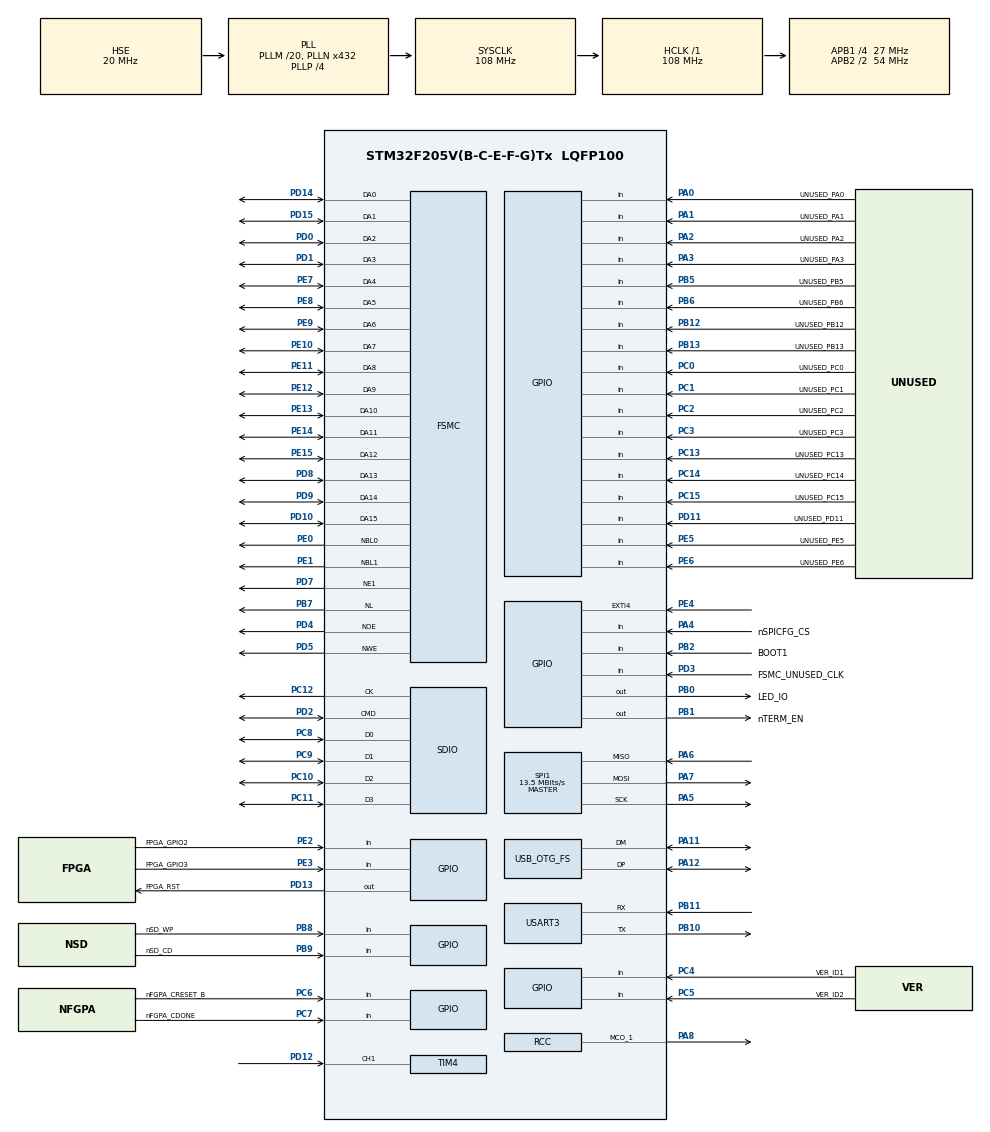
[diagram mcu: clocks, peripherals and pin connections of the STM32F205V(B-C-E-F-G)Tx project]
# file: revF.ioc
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Dma.MEMTOMEM.0.Direction=DMA_MEMORY_TO_MEMORY
Dma.MEMTOMEM.0.FIFOMode=DMA_FIFOMODE_ENABLE
Dma.MEMTOMEM.0.FIFOThreshold=DMA_FIFO_THRESHOLD_FULL
Dma.MEMTOMEM.0.Instance=DMA2_Stream0
Dma.MEMTOMEM.0.MemBurst=DMA_MBURST_INC8
Dma.MEMTOMEM.0.MemDataAlignment=DMA_MDATAALIGN_HALFWORD
Dma.MEMTOMEM.0.MemInc=DMA_MINC_DISABLE
Dma.MEMTOMEM.0.Mode=DMA_NORMAL
Dma.MEMTOMEM.0.PeriphBurst=DMA_PBURST_INC4
Dma.MEMTOMEM.0.PeriphDataAlignment=DMA_PDATAALIGN_WORD
Dma.MEMTOMEM.0.PeriphInc=DMA_PINC_ENABLE
Dma.MEMTOMEM.0.Priority=DMA_PRIORITY_LOW
Dma.MEMTOMEM.1.Direction=DMA_MEMORY_TO_MEMORY
Dma.MEMTOMEM.1.FIFOMode=DMA_FIFOMODE_ENABLE
Dma.MEMTOMEM.1.FIFOThreshold=DMA_FIFO_THRESHOLD_FULL
Dma.MEMTOMEM.1.Instance=DMA2_Stream1
Dma.MEMTOMEM.1.MemBurst=DMA_MBURST_INC4
Dma.MEMTOMEM.1.MemDataAlignment=DMA_MDATAALIGN_WORD
Dma.MEMTOMEM.1.MemInc=DMA_MINC_ENABLE
Dma.MEMTOMEM.1.Mode=DMA_NORMAL
Dma.MEMTOMEM.1.PeriphBurst=DMA_PBURST_INC8
Dma.MEMTOMEM.1.PeriphDataAlignment=DMA_PDATAALIGN_HALFWORD
Dma.MEMTOMEM.1.PeriphInc=DMA_PINC_DISABLE
Dma.MEMTOMEM.1.Priority=DMA_PRIORITY_LOW
Dma.Request0=MEMTOMEM
Dma.Request1=MEMTOMEM
Dma.Request2=SDIO_TX
Dma.Request3=SDIO_RX
Dma.SDIO_RX.3.Direction=DMA_PERIPH_TO_MEMORY
Dma.SDIO_RX.3.FIFOMode=DMA_FIFOMODE_ENABLE
Dma.SDIO_RX.3.FIFOThreshold=DMA_FIFO_THRESHOLD_FULL
Dma.SDIO_RX.3.Instance=DMA2_Stream6
Dma.SDIO_RX.3.MemBurst=DMA_MBURST_INC4
Dma.SDIO_RX.3.MemDataAlignment=DMA_MDATAALIGN_WORD
Dma.SDIO_RX.3.MemInc=DMA_MINC_ENABLE
Dma.SDIO_RX.3.Mode=DMA_PFCTRL
Dma.SDIO_RX.3.PeriphBurst=DMA_PBURST_INC4
Dma.SDIO_RX.3.PeriphDataAlignment=DMA_PDATAALIGN_WORD
Dma.SDIO_RX.3.PeriphInc=DMA_PINC_DISABLE
Dma.SDIO_RX.3.Priority=DMA_PRIORITY_VERY_HIGH
Dma.SDIO_TX.2.Direction=DMA_MEMORY_TO_PERIPH
Dma.SDIO_TX.2.FIFOMode=DMA_FIFOMODE_ENABLE
Dma.SDIO_TX.2.FIFOThreshold=DMA_FIFO_THRESHOLD_FULL
Dma.SDIO_TX.2.Instance=DMA2_Stream3
Dma.SDIO_TX.2.MemBurst=DMA_MBURST_INC4
Dma.SDIO_TX.2.MemDataAlignment=DMA_MDATAALIGN_WORD
Dma.SDIO_TX.2.MemInc=DMA_MINC_ENABLE
Dma.SDIO_TX.2.Mode=DMA_PFCTRL
Dma.SDIO_TX.2.PeriphBurst=DMA_PBURST_INC4
Dma.SDIO_TX.2.PeriphDataAlignment=DMA_PDATAALIGN_WORD
Dma.SDIO_TX.2.PeriphInc=DMA_PINC_DISABLE
Dma.SDIO_TX.2.Priority=DMA_PRIORITY_VERY_HIGH
FSMC.AddressHoldTime1=1
FSMC.AddressSetupTime1=2
FSMC.BusTurnAroundDuration1=1
FSMC.DataSetupTime1=4
FSMC.WriteOperation1=FSMC_WRITE_OPERATION_ENABLE
Mcu.Family=STM32F2
Mcu.Name=STM32F205V(B-C-E-F-G)Tx
Mcu.Package=LQFP100
NVIC.DMA2_Stream3_IRQn=true\:2\:0\:true\:false\:true\:true\:true
NVIC.DMA2_Stream6_IRQn=true\:2\:0\:true\:false\:true\:true\:true
NVIC.EXTI4_IRQn=true\:10\:0\:true\:false\:true\:true\:true
NVIC.OTG_FS_IRQn=true\:1\:0\:true\:false\:true\:true\:true
NVIC.PriorityGroup=NVIC_PRIORITYGROUP_4
NVIC.SDIO_IRQn=true\:8\:0\:true\:false\:true\:true\:true
PA0-WKUP.GPIO_Label=UNUSED_PA0
PA0-WKUP.GPIO_PuPd=GPIO_PULLDOWN
PA0-WKUP.Signal=GPIO_Input
PA1.GPIO_Label=UNUSED_PA1
PA1.GPIO_PuPd=GPIO_PULLDOWN
PA1.Signal=GPIO_Input
PA11.Mode=Device_Only
PA11.Signal=USB_OTG_FS_DM
PA12.Mode=Device_Only
PA12.Signal=USB_OTG_FS_DP
PA2.GPIO_Label=UNUSED_PA2
PA2.GPIO_PuPd=GPIO_PULLDOWN
PA2.Signal=GPIO_Input
PA3.GPIO_Label=UNUSED_PA3
PA3.GPIO_PuPd=GPIO_PULLDOWN
PA3.Signal=GPIO_Input
PA4.GPIO_Label=nSPICFG_CS
PA4.GPIO_Mode=GPIO_MODE_INPUT
PA4.GPIO_PuPd=GPIO_NOPULL
PA4.Signal=GPIO_Input
PA5.Mode=Full_Duplex_Master
PA5.Signal=SPI1_SCK
PA6.Mode=Full_Duplex_Master
PA6.Signal=SPI1_MISO
PA7.Mode=Full_Duplex_Master
PA7.Signal=SPI1_MOSI
PA8.GPIO_Speed=GPIO_SPEED_FREQ_VERY_HIGH
PA8.Mode=Clock-out-1
PA8.Signal=RCC_MCO_1
PB0.GPIO_Label=LED_IO
PB0.GPIO_ModeDefaultOutputPP=GPIO_MODE_OUTPUT_PP
PB0.GPIO_PuPd=GPIO_PULLDOWN
PB0.Signal=GPIO_Output
PB1.GPIO_Label=nTERM_EN
PB1.GPIO_PuPd=GPIO_NOPULL
PB1.Signal=GPIO_Output
PB10.Mode=Asynchronous
PB10.Signal=USART3_TX
PB11.Mode=Asynchronous
PB11.Signal=USART3_RX
PB12.GPIO_Label=UNUSED_PB12
PB12.GPIO_PuPd=GPIO_PULLDOWN
PB12.Signal=GPIO_Input
PB13.GPIO_Label=UNUSED_PB13
PB13.GPIO_PuPd=GPIO_PULLDOWN
PB13.Signal=GPIO_Input
PB2.GPIO_Label=BOOT1
PB2.Signal=GPIO_Input
PB5.GPIO_Label=UNUSED_PB5
PB5.Signal=GPIO_Input
PB6.GPIO_Label=UNUSED_PB6
PB6.Signal=GPIO_Input
PB7.GPIO_Speed_High_Default=GPIO_SPEED_FREQ_MEDIUM
PB7.Signal=FSMC_NL
PB8.GPIO_Label=nSD_WP
PB8.GPIO_PuPd=GPIO_PULLUP
PB8.Signal=GPIO_Input
PB9.GPIO_Label=nSD_CD
PB9.GPIO_PuPd=GPIO_PULLUP
PB9.Signal=GPIO_Input
PC0.GPIO_Label=UNUSED_PC0
PC0.GPIO_PuPd=GPIO_PULLDOWN
PC0.Signal=GPIO_Input
PC1.GPIO_Label=UNUSED_PC1
PC1.GPIO_PuPd=GPIO_PULLDOWN
PC1.Signal=GPIO_Input
PC10.GPIO_PuPd=GPIO_PULLUP
PC10.Mode=SD_4_bits_Wide_bus
PC10.Signal=SDIO_D2
PC11.GPIO_PuPd=GPIO_PULLUP
PC11.Mode=SD_4_bits_Wide_bus
PC11.Signal=SDIO_D3
PC12.Mode=SD_4_bits_Wide_bus
PC12.Signal=SDIO_CK
PC13.GPIO_Label=UNUSED_PC13
PC13.GPIO_PuPd=GPIO_PULLDOWN
PC13.Signal=GPIO_Input
PC14-OSC32_IN.GPIO_Label=UNUSED_PC14
PC14-OSC32_IN.GPIO_PuPd=GPIO_PULLDOWN
PC14-OSC32_IN.Signal=GPIO_Input
PC15-OSC32_OUT.GPIO_Label=UNUSED_PC15
PC15-OSC32_OUT.GPIO_PuPd=GPIO_PULLDOWN
PC15-OSC32_OUT.Signal=GPIO_Input
PC2.GPIO_Label=UNUSED_PC2
PC2.GPIO_PuPd=GPIO_PULLDOWN
PC2.Signal=GPIO_Input
PC3.GPIO_Label=UNUSED_PC3
PC3.GPIO_PuPd=GPIO_PULLDOWN
PC3.Signal=GPIO_Input
PC4.GPIO_Label=VER_ID1
PC4.GPIO_PuPd=GPIO_PULLUP
PC4.Signal=GPIO_Input
PC5.GPIO_Label=VER_ID2
PC5.GPIO_PuPd=GPIO_PULLUP
PC5.Signal=GPIO_Input
PC6.GPIO_Label=nFGPA_CRESET_B
PC6.GPIO_PuPd=GPIO_NOPULL
PC6.Signal=GPIO_Input
PC7.GPIO_Label=nFGPA_CDONE
PC7.GPIO_PuPd=GPIO_NOPULL
PC7.Signal=GPIO_Input
PC8.GPIO_PuPd=GPIO_PULLUP
PC8.Mode=SD_4_bits_Wide_bus
PC8.Signal=SDIO_D0
PC9.GPIO_PuPd=GPIO_PULLUP
PC9.Mode=SD_4_bits_Wide_bus
PC9.Signal=SDIO_D1
PD0.GPIO_Speed_High_Default=GPIO_SPEED_FREQ_MEDIUM
PD0.Mode=16b-da1
PD0.Signal=FSMC_DA2
PD1.GPIO_Speed_High_Default=GPIO_SPEED_FREQ_MEDIUM
PD1.Mode=16b-da1
PD1.Signal=FSMC_DA3
PD10.GPIO_Speed_High_Default=GPIO_SPEED_FREQ_MEDIUM
PD10.Mode=16b-da1
PD10.Signal=FSMC_DA15
PD11.GPIO_Label=UNUSED_PD11
PD11.GPIO_PuPd=GPIO_PULLDOWN
PD11.Signal=GPIO_Input
PD12.Signal=S_TIM4_CH1
PD13.GPIO_Label=FPGA_RST
PD13.GPIO_PuPd=GPIO_NOPULL
PD13.Signal=GPIO_Output
PD14.GPIO_Speed_High_Default=GPIO_SPEED_FREQ_MEDIUM
PD14.Mode=16b-da1
PD14.Signal=FSMC_DA0
PD15.GPIO_Speed_High_Default=GPIO_SPEED_FREQ_MEDIUM
PD15.Mode=16b-da1
PD15.Signal=FSMC_DA1
PD2.GPIO_PuPd=GPIO_PULLUP
PD2.Mode=SD_4_bits_Wide_bus
PD2.Signal=SDIO_CMD
PD3.GPIO_Label=FSMC_UNUSED_CLK
PD3.GPIO_PuPd=GPIO_PULLDOWN
PD3.Signal=GPIO_Input
PD4.GPIO_Speed_High_Default=GPIO_SPEED_FREQ_MEDIUM
PD4.Mode=MuxedPsram1
PD4.Signal=FSMC_NOE
PD5.GPIO_Speed_High_Default=GPIO_SPEED_FREQ_MEDIUM
PD5.Mode=MuxedPsram1
PD5.Signal=FSMC_NWE
PD7.GPIO_Speed_High_Default=GPIO_SPEED_FREQ_MEDIUM
PD7.Mode=NorPsramChipSelect1_1
PD7.Signal=FSMC_NE1
PD8.GPIO_Speed_High_Default=GPIO_SPEED_FREQ_MEDIUM
PD8.Mode=16b-da1
PD8.Signal=FSMC_DA13
PD9.GPIO_Speed_High_Default=GPIO_SPEED_FREQ_MEDIUM
PD9.Mode=16b-da1
PD9.Signal=FSMC_DA14
PE0.GPIO_Speed_High_Default=GPIO_SPEED_FREQ_MEDIUM
PE0.Mode=2ByteEnable1
PE0.Signal=FSMC_NBL0
PE1.GPIO_Speed_High_Default=GPIO_SPEED_FREQ_MEDIUM
PE1.Mode=2ByteEnable1
PE1.Signal=FSMC_NBL1
PE10.GPIO_Speed_High_Default=GPIO_SPEED_FREQ_MEDIUM
PE10.Mode=16b-da1
PE10.Signal=FSMC_DA7
PE11.GPIO_Speed_High_Default=GPIO_SPEED_FREQ_MEDIUM
PE11.Mode=16b-da1
PE11.Signal=FSMC_DA8
PE12.GPIO_Speed_High_Default=GPIO_SPEED_FREQ_MEDIUM
PE12.Mode=16b-da1
PE12.Signal=FSMC_DA9
PE13.GPIO_Speed_High_Default=GPIO_SPEED_FREQ_MEDIUM
PE13.Mode=16b-da1
PE13.Signal=FSMC_DA10
PE14.GPIO_Speed_High_Default=GPIO_SPEED_FREQ_MEDIUM
PE14.Mode=16b-da1
PE14.Signal=FSMC_DA11
PE15.GPIO_Speed_High_Default=GPIO_SPEED_FREQ_MEDIUM
PE15.Mode=16b-da1
PE15.Signal=FSMC_DA12
PE2.GPIO_Label=FPGA_GPIO2
PE2.GPIO_PuPd=GPIO_PULLDOWN
PE2.Signal=GPIO_Input
PE3.GPIO_Label=FPGA_GPIO3
PE3.GPIO_PuPd=GPIO_PULLDOWN
PE3.Signal=GPIO_Input
PE4.Signal=GPXTI4
PE5.GPIO_Label=UNUSED_PE5
PE5.GPIO_PuPd=GPIO_PULLDOWN
PE5.Signal=GPIO_Input
PE6.GPIO_Label=UNUSED_PE6
PE6.GPIO_PuPd=GPIO_PULLDOWN
PE6.Signal=GPIO_Input
PE7.GPIO_Speed_High_Default=GPIO_SPEED_FREQ_MEDIUM
PE7.Mode=16b-da1
PE7.Signal=FSMC_DA4
PE8.GPIO_Speed_High_Default=GPIO_SPEED_FREQ_MEDIUM
PE8.Mode=16b-da1
PE8.Signal=FSMC_DA5
PE9.GPIO_Speed_High_Default=GPIO_SPEED_FREQ_MEDIUM
PE9.Mode=16b-da1
PE9.Signal=FSMC_DA6
PH0-OSC_IN.Mode=HSE-External-Oscillator
PH0-OSC_IN.Signal=RCC_OSC_IN
PH1-OSC_OUT.Mode=HSE-External-Oscillator
PH1-OSC_OUT.Signal=RCC_OSC_OUT
ProjectManager.HeapSize=0x200
ProjectManager.StackSize=0x400
ProjectManager.TargetToolchain=TrueSTUDIO
RCC.48MHZClocksFreq_Value=48000000
RCC.AHBFreq_Value=108000000
RCC.APB1CLKDivider=RCC_HCLK_DIV4
RCC.APB1Freq_Value=27000000
RCC.APB1TimFreq_Value=54000000
RCC.APB2CLKDivider=RCC_HCLK_DIV2
RCC.APB2Freq_Value=54000000
RCC.APB2TimFreq_Value=108000000
RCC.CortexFreq_Value=108000000
RCC.HCLKFreq_Value=108000000
RCC.HSE_VALUE=20000000
RCC.HSI_VALUE=16000000
RCC.LSE_VALUE=32768
RCC.PLLM=20
RCC.PLLN=432
RCC.PLLP=RCC_PLLP_DIV4
RCC.PLLQ=9
RCC.PLLSourceVirtual=RCC_PLLSOURCE_HSE
RCC.RCC_MCO1Source=RCC_MCO1SOURCE_PLLCLK
RCC.SYSCLKFreq_VALUE=108000000
RCC.SYSCLKSource=RCC_SYSCLKSOURCE_PLLCLK
RCC.VCOOutputFreq_Value=432000000
SDIO.WideMode=SDIO_BUS_WIDE_4B
SH.FSMC_NL.0=FSMC_NL,AddressValid1
SH.S_TIM4_CH1.0=TIM4_CH1,TriggerSource_TI1FP1
SPI1.BaudRatePrescaler=SPI_BAUDRATEPRESCALER_4
SPI1.CLKPhase=SPI_PHASE_2EDGE
SPI1.CLKPolarity=SPI_POLARITY_HIGH
SPI1.CalculateBaudRate=13.5 MBits/s
SPI1.Direction=SPI_DIRECTION_2LINES
SPI1.Mode=SPI_MODE_MASTER
SPI1.VirtualType=VM_MASTER
USART3.VirtualMode=VM_ASYNC
USB_DEVICE.CLASS_NAME_FS=MSC
USB_DEVICE.VirtualMode-MSC_FS=Msc
USB_DEVICE.VirtualModeFS=Msc_FS
USB_OTG_FS.VirtualMode=Device_Only
VP_TIM4_VS_ControllerModeClock.Mode=Clock Mode
VP_USB_DEVICE_VS_USB_DEVICE_MSC_FS.Mode=MSC_FS
board=SCSI2SD-V6

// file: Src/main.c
/* USER CODE BEGIN Header */
/**
  ******************************************************************************
  * @file           : main.c
  * @brief          : Main program body
  ******************************************************************************
  * @attention
  *
  * <h2><center>&copy; Copyright (c) 2021 STMicroelectronics.
  * All rights reserved.</center></h2>
  *
  * This software component is licensed by ST under Ultimate Liberty license
  * SLA0044, the "License"; You may not use this file except in compliance with
  * the License. You may obtain a copy of the License at:
  *                             www.st.com/SLA0044
  *
  ******************************************************************************
  */
/* USER CODE END Header */

#include "main.h"
#include "dma.h"
#include "sdio.h"
#include "spi.h"
#include "tim.h"
#include "usart.h"
#include "usb_device.h"
#include "gpio.h"
#include "fsmc.h"

/* USER CODE BEGIN PV */
/* Private variables ---------------------------------------------------------*/

/* USER CODE END PV */

void SystemClock_Config(void);
/* USER CODE BEGIN PFP */
/* Private function prototypes -----------------------------------------------*/
void mainEarlyInit();
void mainInit();
void mainLoop();

/* USER CODE END PFP */

int main(void)
{
  /* USER CODE BEGIN 1 */
  mainEarlyInit();

  /* USER CODE END 1 */

  /* MCU Configuration--------------------------------------------------------*/

  /* Reset of all peripherals, Initializes the Flash interface and the Systick. */
  HAL_Init();

  /* Configure the system clock */
  SystemClock_Config();

  /* Initialize all configured peripherals */
  MX_GPIO_Init();
  MX_DMA_Init();
  MX_FSMC_Init();
  MX_SDIO_SD_Init();
  MX_SPI1_Init();
  MX_TIM4_Init();
  MX_USART3_UART_Init();
  MX_USB_DEVICE_Init();
  /* USER CODE BEGIN 2 */
  mainInit();

  /* USER CODE END 2 */

  /* Infinite loop */
  while (1)
  {

    /* USER CODE BEGIN 3 */
  mainLoop();

  }
  /* USER CODE END 3 */
}

void SystemClock_Config(void)
{
  RCC_OscInitTypeDef RCC_OscInitStruct = {0};
  RCC_ClkInitTypeDef RCC_ClkInitStruct = {0};

  /** Initializes the CPU, AHB and APB busses clocks
  */
  RCC_OscInitStruct.OscillatorType = RCC_OSCILLATORTYPE_HSE;
  RCC_OscInitStruct.HSEState = RCC_HSE_ON;
  RCC_OscInitStruct.PLL.PLLState = RCC_PLL_ON;
  RCC_OscInitStruct.PLL.PLLSource = RCC_PLLSOURCE_HSE;
  RCC_OscInitStruct.PLL.PLLM = 20;
  RCC_OscInitStruct.PLL.PLLN = 432;
  RCC_OscInitStruct.PLL.PLLP = RCC_PLLP_DIV4;
  RCC_OscInitStruct.PLL.PLLQ = 9;
  if (HAL_RCC_OscConfig(&RCC_OscInitStruct) != HAL_OK)
  {
    Error_Handler();
  }
  /** Initializes the CPU, AHB and APB busses clocks
  */
  RCC_ClkInitStruct.ClockType = RCC_CLOCKTYPE_HCLK|RCC_CLOCKTYPE_SYSCLK
                              |RCC_CLOCKTYPE_PCLK1|RCC_CLOCKTYPE_PCLK2;
  RCC_ClkInitStruct.SYSCLKSource = RCC_SYSCLKSOURCE_PLLCLK;
  RCC_ClkInitStruct.AHBCLKDivider = RCC_SYSCLK_DIV1;
  RCC_ClkInitStruct.APB1CLKDivider = RCC_HCLK_DIV4;
  RCC_ClkInitStruct.APB2CLKDivider = RCC_HCLK_DIV2;

  if (HAL_RCC_ClockConfig(&RCC_ClkInitStruct, FLASH_LATENCY_3) != HAL_OK)
  {
    Error_Handler();
  }
  HAL_RCC_MCOConfig(RCC_MCO1, RCC_MCO1SOURCE_PLLCLK, RCC_MCODIV_1);
}

void Error_Handler(void)
{
}

/************************ (C) COPYRIGHT STMicroelectronics *****END OF FILE****/
